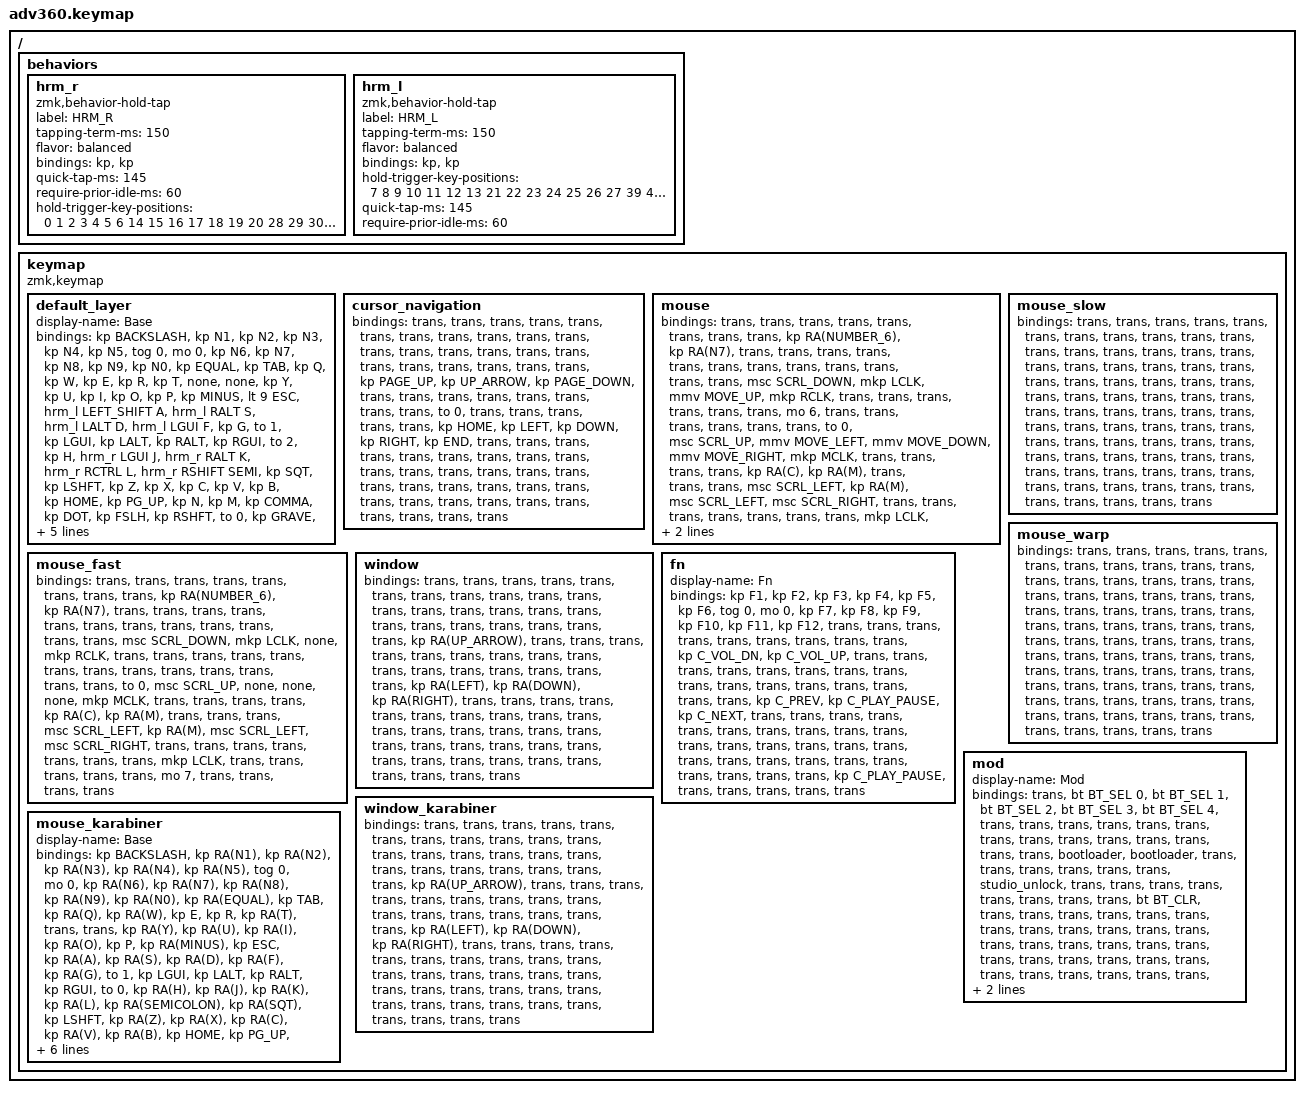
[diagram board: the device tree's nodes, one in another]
#include <dt-bindings/zmk/stp.h>
#include <behaviors.dtsi>
#include <dt-bindings/zmk/backlight.h>
#include <dt-bindings/zmk/bt.h>
#include <dt-bindings/zmk/keys.h>
#include <dt-bindings/zmk/pointing.h>
#include <dt-bindings/zmk/rgb.h>

/ {
    behaviors {
        #include "macros.dtsi"
      #include "version.dtsi"

        hrm_r: hrm_r {
            compatible = "zmk,behavior-hold-tap";
            label = "HRM_R";
            #binding-cells = <2>;
            tapping-term-ms = <150>;
            flavor = "balanced";
            bindings = <&kp>, <&kp>;

            quick-tap-ms = <145>;
            require-prior-idle-ms = <60>;
            hold-trigger-key-positions = <0 1 2 3 4 5 6 14 15 16 17 18 19 20 28 29 30 31 32 33 34 46 47 48 49 50 51 60 61 62 63 64 65 66 52 36 35 67 70 68 69 37 38 53>;
        };

        hrm_l: hrm_l {
            compatible = "zmk,behavior-hold-tap";
            label = "HRM_L";
            #binding-cells = <2>;
            tapping-term-ms = <150>;
            flavor = "balanced";
            bindings = <&kp>, <&kp>;

            hold-trigger-key-positions = <7 8 9 10 11 12 13 21 22 23 24 25 26 27 39 40 41 42 43 44 45 54 55 56 57 58 59 71 72 73 74 75 53 69 70 38 37 68 35 36 52 65 66 67>;
            quick-tap-ms = <145>;
            require-prior-idle-ms = <60>;
        };
    };

    keymap {
        compatible = "zmk,keymap";

        default_layer {
            display-name = "Base";
            bindings = <
&kp BACKSLASH  &kp N1               &kp N2              &kp N3         &kp N4          &kp N5  &tog 0                                                                &mo 0        &kp N6  &kp N7             &kp N8         &kp N9          &kp N0              &kp EQUAL
&kp TAB        &kp Q                &kp W               &kp E          &kp R           &kp T   &none                                                                 &none        &kp Y   &kp U              &kp I          &kp O           &kp P               &kp MINUS
&lt 9 ESC      &hrm_l LEFT_SHIFT A  &hrm_l RALT S       &hrm_l LALT D  &hrm_l LGUI F   &kp G   &to 1            &kp LGUI         &kp LALT      &kp RALT   &kp RGUI   &to 2        &kp H   &hrm_r LGUI J      &hrm_r RALT K  &hrm_r RCTRL L  &hrm_r RSHIFT SEMI  &kp SQT
&kp LSHFT      &kp Z                &kp X               &kp C          &kp V           &kp B                                     &kp HOME      &kp PG_UP                          &kp N   &kp M              &kp COMMA      &kp DOT         &kp FSLH            &kp RSHFT
&to 0          &kp GRAVE            &mt LCTRL CAPSLOCK  &mt LALT LEFT  &mt LGUI RIGHT          &lt 1 BACKSPACE  &lt 7 LG(GRAVE)  &kp END       &kp PG_DN  &kp ENTER  &lt 9 SPACE          &mt RGUI UP_ARROW  &mt RALT DOWN  &mt RCTRL LBKT  &kp RBKT            &mo 8
            >;
        };

        cursor_navigation {
            bindings = <
&trans  &trans  &trans  &trans  &trans  &trans  &trans                                      &trans  &trans    &trans       &trans        &trans         &trans   &trans
&trans  &trans  &trans  &trans  &trans  &trans  &trans                                      &trans  &trans    &kp PAGE_UP  &kp UP_ARROW  &kp PAGE_DOWN  &trans   &trans
&trans  &trans  &trans  &trans  &trans  &trans  &to 0   &trans  &trans      &trans  &trans  &trans  &kp HOME  &kp LEFT     &kp DOWN      &kp RIGHT      &kp END  &trans
&trans  &trans  &trans  &trans  &trans  &trans                  &trans      &trans                  &trans    &trans       &trans        &trans         &trans   &trans
&trans  &trans  &trans  &trans  &trans          &trans  &trans  &trans      &trans  &trans  &trans            &trans       &trans        &trans         &trans   &trans
            >;
        };

        mouse {
            bindings = <
&trans  &trans  &trans  &trans     &trans     &trans  &trans                                         &trans  &kp RA(NUMBER_6)  &kp RA(N7)      &trans          &trans           &trans     &trans
&trans  &trans  &trans  &trans     &trans     &trans  &trans                                         &trans  &msc SCRL_DOWN    &mkp LCLK       &mmv MOVE_UP    &mkp RCLK        &trans     &trans
&trans  &trans  &trans  &trans     &mo 6      &trans  &trans     &trans  &trans      &trans  &trans  &to 0   &msc SCRL_UP      &mmv MOVE_LEFT  &mmv MOVE_DOWN  &mmv MOVE_RIGHT  &mkp MCLK  &trans
&trans  &trans  &trans  &kp RA(C)  &kp RA(M)  &trans                     &trans      &trans                  &msc SCRL_LEFT    &kp RA(M)       &msc SCRL_LEFT  &msc SCRL_RIGHT  &trans     &trans
&trans  &trans  &trans  &trans     &trans             &mkp LCLK  &trans  &trans      &trans  &trans  &trans                    &trans          &trans          &trans           &trans     &trans
            >;
        };

        mouse_slow {
            bindings = <
&trans  &trans  &trans  &trans  &trans  &trans  &trans                                      &trans  &trans  &trans  &trans  &trans  &trans  &trans
&trans  &trans  &trans  &trans  &trans  &trans  &trans                                      &trans  &trans  &trans  &trans  &trans  &trans  &trans
&trans  &trans  &trans  &trans  &trans  &trans  &trans  &trans  &trans      &trans  &trans  &trans  &trans  &trans  &trans  &trans  &trans  &trans
&trans  &trans  &trans  &trans  &trans  &trans                  &trans      &trans                  &trans  &trans  &trans  &trans  &trans  &trans
&trans  &trans  &trans  &trans  &trans          &trans  &trans  &trans      &trans  &trans  &trans          &trans  &trans  &trans  &trans  &trans
            >;
        };

        mouse_warp {
            bindings = <
&trans  &trans  &trans  &trans  &trans  &trans  &trans                                      &trans  &trans  &trans  &trans  &trans  &trans  &trans
&trans  &trans  &trans  &trans  &trans  &trans  &trans                                      &trans  &trans  &trans  &trans  &trans  &trans  &trans
&trans  &trans  &trans  &trans  &trans  &trans  &trans  &trans  &trans      &trans  &trans  &trans  &trans  &trans  &trans  &trans  &trans  &trans
&trans  &trans  &trans  &trans  &trans  &trans                  &trans      &trans                  &trans  &trans  &trans  &trans  &trans  &trans
&trans  &trans  &trans  &trans  &trans          &trans  &trans  &trans      &trans  &trans  &trans          &trans  &trans  &trans  &trans  &trans
            >;
        };

        mouse_fast {
            bindings = <
&trans  &trans  &trans  &trans     &trans     &trans  &trans                                         &trans  &kp RA(NUMBER_6)  &kp RA(N7)  &trans          &trans           &trans     &trans
&trans  &trans  &trans  &trans     &trans     &trans  &trans                                         &trans  &msc SCRL_DOWN    &mkp LCLK   &none           &mkp RCLK        &trans     &trans
&trans  &trans  &trans  &trans     &trans     &trans  &trans     &trans  &trans      &trans  &trans  &to 0   &msc SCRL_UP      &none       &none           &none            &mkp MCLK  &trans
&trans  &trans  &trans  &kp RA(C)  &kp RA(M)  &trans                     &trans      &trans                  &msc SCRL_LEFT    &kp RA(M)   &msc SCRL_LEFT  &msc SCRL_RIGHT  &trans     &trans
&trans  &trans  &trans  &trans     &trans             &mkp LCLK  &trans  &trans      &trans  &trans  &trans                    &mo 7       &trans          &trans           &trans     &trans
            >;
        };

        window {
            bindings = <
&trans  &trans  &trans  &trans  &trans  &trans  &trans                                      &trans  &trans  &trans        &trans            &trans         &trans  &trans
&trans  &trans  &trans  &trans  &trans  &trans  &trans                                      &trans  &trans  &trans        &kp RA(UP_ARROW)  &trans         &trans  &trans
&trans  &trans  &trans  &trans  &trans  &trans  &trans  &trans  &trans      &trans  &trans  &trans  &trans  &kp RA(LEFT)  &kp RA(DOWN)      &kp RA(RIGHT)  &trans  &trans
&trans  &trans  &trans  &trans  &trans  &trans                  &trans      &trans                  &trans  &trans        &trans            &trans         &trans  &trans
&trans  &trans  &trans  &trans  &trans          &trans  &trans  &trans      &trans  &trans  &trans          &trans        &trans            &trans         &trans  &trans
            >;
        };

        fn {
            display-name = "Fn";
            bindings = <
&kp F1  &kp F2  &kp F3  &kp F4  &kp F5  &kp F6  &tog 0                                      &mo 0             &kp F7  &kp F8        &kp F9            &kp F10     &kp F11  &kp F12
&trans  &trans  &trans  &trans  &trans  &trans  &trans                                      &trans            &trans  &kp C_VOL_DN  &kp C_VOL_UP      &trans      &trans   &trans
&trans  &trans  &trans  &trans  &trans  &trans  &trans  &trans  &trans      &trans  &trans  &trans            &trans  &kp C_PREV    &kp C_PLAY_PAUSE  &kp C_NEXT  &trans   &trans
&trans  &trans  &trans  &trans  &trans  &trans                  &trans      &trans                            &trans  &trans        &trans            &trans      &trans   &trans
&trans  &trans  &trans  &trans  &trans          &trans  &trans  &trans      &trans  &trans  &kp C_PLAY_PAUSE          &trans        &trans            &trans      &trans   &trans
            >;
        };

        mod {
            display-name = "Mod";
            bindings = <
&trans          &bt BT_SEL 0  &bt BT_SEL 1  &bt BT_SEL 2  &bt BT_SEL 3  &bt BT_SEL 4  &trans                                                   &trans           &trans  &trans      &trans      &trans  &trans  &trans
&trans          &trans        &trans        &trans        &trans        &trans        &bootloader                                              &bootloader      &trans  &trans      &trans      &trans  &trans  &trans
&studio_unlock  &trans        &trans        &trans        &trans        &trans        &trans       &trans  &trans      &bt BT_CLR  &trans      &trans           &trans  &trans      &trans      &trans  &trans  &trans
&trans          &trans        &trans        &trans        &trans        &trans                             &trans      &trans                                   &trans  &trans      &trans      &trans  &trans  &trans
&trans          &trans        &trans        &trans        &trans                      &trans       &trans  &trans      &trans      &bl BL_TOG  &rgb_ug RGB_TOG          &bl BL_INC  &bl BL_DEC  &trans  &trans  &trans
            >;
        };

        mouse_karabiner {
            display-name = "Base";
            bindings = <
&kp BACKSLASH  &kp RA(N1)  &kp RA(N2)          &kp RA(N3)     &kp RA(N4)      &kp RA(N5)  &tog 0                                                              &mo 0      &kp RA(N6)  &kp RA(N7)  &kp RA(N8)     &kp RA(N9)      &kp RA(N0)         &kp RA(EQUAL)
&kp TAB        &kp RA(Q)   &kp RA(W)           &kp E          &kp R           &kp RA(T)   &trans                                                              &trans     &kp RA(Y)   &kp RA(U)   &kp RA(I)      &kp RA(O)       &kp P              &kp RA(MINUS)
&kp ESC        &kp RA(A)   &kp RA(S)           &kp RA(D)      &kp RA(F)       &kp RA(G)   &to 1          &kp LGUI         &kp LALT      &kp RALT   &kp RGUI   &to 0      &kp RA(H)   &kp RA(J)   &kp RA(K)      &kp RA(L)       &kp RA(SEMICOLON)  &kp RA(SQT)
&kp LSHFT      &kp RA(Z)   &kp RA(X)           &kp RA(C)      &kp RA(V)       &kp RA(B)                                   &kp HOME      &kp PG_UP                        &kp RA(N)   &kp RA(M)   &kp RA(COMMA)  &kp RA(DOT)     &kp RA(FSLH)       &kp RSHFT
&to 0          &kp GRAVE   &mt LCTRL CAPSLOCK  &mt LALT LEFT  &mt LGUI RIGHT              &kp RA(SPACE)  &lt 7 LG(GRAVE)  &kp END       &kp PG_DN  &kp ENTER  &kp SPACE              &mo 10      &mt RALT DOWN  &mt RCTRL LBKT  &kp RBKT           &mo 8
            >;
        };

        window_karabiner {
            bindings = <
&trans  &trans  &trans  &trans  &trans  &trans  &trans                                      &trans  &trans  &trans        &trans            &trans         &trans  &trans
&trans  &trans  &trans  &trans  &trans  &trans  &trans                                      &trans  &trans  &trans        &kp RA(UP_ARROW)  &trans         &trans  &trans
&trans  &trans  &trans  &trans  &trans  &trans  &trans  &trans  &trans      &trans  &trans  &trans  &trans  &kp RA(LEFT)  &kp RA(DOWN)      &kp RA(RIGHT)  &trans  &trans
&trans  &trans  &trans  &trans  &trans  &trans                  &trans      &trans                  &trans  &trans        &trans            &trans         &trans  &trans
&trans  &trans  &trans  &trans  &trans          &trans  &trans  &trans      &trans  &trans  &trans          &trans        &trans            &trans         &trans  &trans
            >;
        };
    };
};
